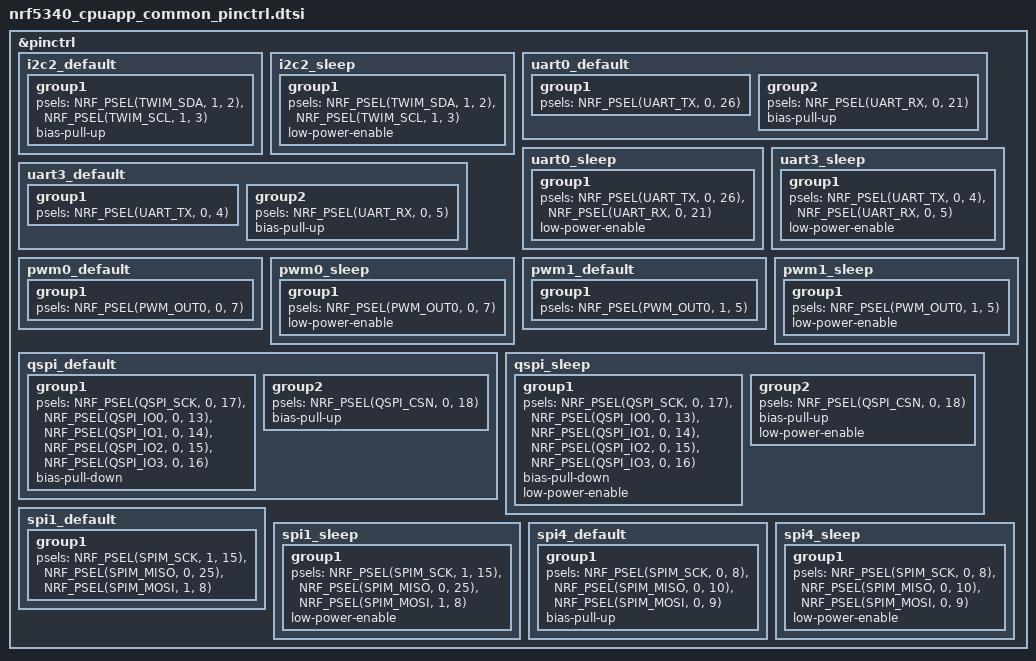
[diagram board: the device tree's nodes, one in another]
&pinctrl {
	
	i2c2_default: i2c2_default {
        group1 {
            psels = <NRF_PSEL(TWIM_SDA, 1, 2)>,
                <NRF_PSEL(TWIM_SCL, 1, 3)>;
            bias-pull-up;
        };

    };

	i2c2_sleep: i2c2_sleep {
        group1 {
            psels = <NRF_PSEL(TWIM_SDA, 1, 2)>,
                <NRF_PSEL(TWIM_SCL, 1, 3)>;
			low-power-enable;
        };
    };

	uart0_default: uart0_default {
		group1 {
			psels = <NRF_PSEL(UART_TX, 0, 26)>;
		};

		group2 {
			psels = <NRF_PSEL(UART_RX, 0, 21)>;
			bias-pull-up;
		};
	};

	uart0_sleep: uart0_sleep {
		group1 {
			psels = <NRF_PSEL(UART_TX, 0, 26)>,
				<NRF_PSEL(UART_RX, 0, 21)>;
			low-power-enable;
		};
	};
	
	
	uart3_default: uart3_default {
		group1 {
			psels = <NRF_PSEL(UART_TX, 0, 4)>;
		};
		group2 {
			psels = <NRF_PSEL(UART_RX, 0, 5)>;
			bias-pull-up;
		};
	};

	uart3_sleep: uart3_sleep {
		group1 {
			psels = <NRF_PSEL(UART_TX, 0, 4)>,
				<NRF_PSEL(UART_RX, 0, 5)>;
			low-power-enable;
		};
	};

	pwm0_default: pwm0_default {
		group1 {
			psels = <NRF_PSEL(PWM_OUT0, 0, 7)>;
		};
	};

	pwm0_sleep: pwm0_sleep {
		group1 {
			psels = <NRF_PSEL(PWM_OUT0, 0, 7)>;
			low-power-enable;
		};
	};
	
	pwm1_default: pwm1_default {
		group1 {
			psels = <NRF_PSEL(PWM_OUT0, 1, 5)>;
		};
	};

	pwm1_sleep: pwm1_sleep {
		group1 {
			psels = <NRF_PSEL(PWM_OUT0, 1, 5)>;
			low-power-enable;
		};
	};

	qspi_default: qspi_default {
		group1 {
			psels = <NRF_PSEL(QSPI_SCK, 0, 17)>,
				<NRF_PSEL(QSPI_IO0, 0, 13)>,
				<NRF_PSEL(QSPI_IO1, 0, 14)>,
				<NRF_PSEL(QSPI_IO2, 0, 15)>,
				<NRF_PSEL(QSPI_IO3, 0, 16)>;
			bias-pull-down;
		};

		group2 {
			psels = <NRF_PSEL(QSPI_CSN, 0, 18)>;
			bias-pull-up;
		};
	};

	qspi_sleep: qspi_sleep {
		group1 {
			psels = <NRF_PSEL(QSPI_SCK, 0, 17)>,
				<NRF_PSEL(QSPI_IO0, 0, 13)>,
				<NRF_PSEL(QSPI_IO1, 0, 14)>,
				<NRF_PSEL(QSPI_IO2, 0, 15)>,
				<NRF_PSEL(QSPI_IO3, 0, 16)>;
			bias-pull-down;
			low-power-enable;
		};

		group2 {
			psels = <NRF_PSEL(QSPI_CSN, 0, 18)>;
			bias-pull-up;
			low-power-enable;
		};
	};


	spi1_default: spi1_default {
        group1 {
            psels = <NRF_PSEL(SPIM_SCK, 1, 15)>,
                <NRF_PSEL(SPIM_MISO, 0, 25)>,
                <NRF_PSEL(SPIM_MOSI, 1, 8)>;
        };
    };

	spi1_sleep: spi1_sleep {
        group1 {
            psels = <NRF_PSEL(SPIM_SCK, 1, 15)>,
                <NRF_PSEL(SPIM_MISO, 0, 25)>,
                <NRF_PSEL(SPIM_MOSI, 1, 8)>;
			low-power-enable;
        };
    };
	

	spi4_default: spi4_default {
		group1 {
			psels = <NRF_PSEL(SPIM_SCK, 0, 8)>,
				<NRF_PSEL(SPIM_MISO, 0, 10)>,
				<NRF_PSEL(SPIM_MOSI, 0, 9)>;
				bias-pull-up; //pull up all SDCard SPI lines
		};
		
	};

	spi4_sleep: spi4_sleep {
		group1 {
			psels = <NRF_PSEL(SPIM_SCK, 0, 8)>,
				<NRF_PSEL(SPIM_MISO, 0, 10)>,
				<NRF_PSEL(SPIM_MOSI, 0, 9)>;
			low-power-enable;
		};
	};
};
